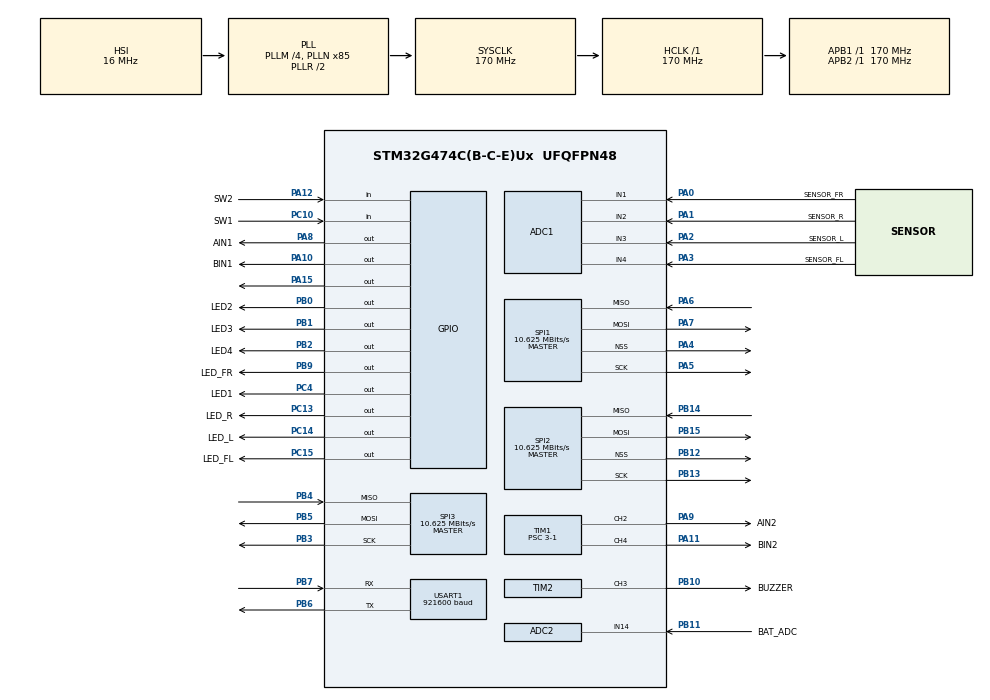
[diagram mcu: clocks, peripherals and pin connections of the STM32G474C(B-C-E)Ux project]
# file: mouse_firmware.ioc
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ADC1.Channel-8\#ChannelRegularConversion=ADC_CHANNEL_1
ADC1.ClockPrescaler=ADC_CLOCK_ASYNC_DIV4
ADC1.ContinuousConvMode=DISABLE
ADC1.DMAContinuousRequests=DISABLE
ADC1.DiscontinuousConvMode=DISABLE
ADC1.EnableRegularConversion=ENABLE
ADC1.NbrOfConversion=1
ADC1.NbrOfConversionFlag=1
ADC1.OffsetNumber-8\#ChannelRegularConversion=ADC_OFFSET_NONE
ADC1.Overrun=ADC_OVR_DATA_PRESERVED
ADC1.Rank-8\#ChannelRegularConversion=1
ADC1.SamplingTime-8\#ChannelRegularConversion=ADC_SAMPLETIME_2CYCLES_5
ADC1.master=1
ADC2.Channel-0\#ChannelRegularConversion=ADC_CHANNEL_14
ADC2.ClockPrescaler=ADC_CLOCK_ASYNC_DIV4
ADC2.ContinuousConvMode=DISABLE
ADC2.DMAContinuousRequests=ENABLE
ADC2.EOCSelection=ADC_EOC_SINGLE_CONV
ADC2.EnableInjectedConversion=DISABLE
ADC2.LowPowerAutoWait=DISABLE
ADC2.NbrOfConversion=1
ADC2.NbrOfConversionFlag=1
ADC2.OffsetNumber-0\#ChannelRegularConversion=ADC_OFFSET_NONE
ADC2.Rank-0\#ChannelRegularConversion=1
ADC2.Rank1_Channel=ADC_CHANNEL_14
ADC2.SamplingTime-0\#ChannelRegularConversion=ADC_SAMPLETIME_12CYCLES_5
Dma.ADC1.0.Direction=DMA_PERIPH_TO_MEMORY
Dma.ADC1.0.EventEnable=DISABLE
Dma.ADC1.0.Instance=DMA1_Channel1
Dma.ADC1.0.MemDataAlignment=DMA_MDATAALIGN_HALFWORD
Dma.ADC1.0.MemInc=DMA_MINC_ENABLE
Dma.ADC1.0.Mode=DMA_NORMAL
Dma.ADC1.0.PeriphDataAlignment=DMA_PDATAALIGN_HALFWORD
Dma.ADC1.0.PeriphInc=DMA_PINC_DISABLE
Dma.ADC1.0.Polarity=HAL_DMAMUX_REQ_GEN_RISING
Dma.ADC1.0.Priority=DMA_PRIORITY_LOW
Dma.ADC1.0.RequestNumber=1
Dma.ADC1.0.SignalID=NONE
Dma.ADC1.0.SyncEnable=DISABLE
Dma.ADC1.0.SyncPolarity=HAL_DMAMUX_SYNC_NO_EVENT
Dma.ADC1.0.SyncRequestNumber=1
Dma.ADC1.0.SyncSignalID=NONE
Dma.ADC2.5.Direction=DMA_PERIPH_TO_MEMORY
Dma.ADC2.5.EventEnable=DISABLE
Dma.ADC2.5.Instance=DMA1_Channel6
Dma.ADC2.5.MemDataAlignment=DMA_MDATAALIGN_HALFWORD
Dma.ADC2.5.MemInc=DMA_MINC_ENABLE
Dma.ADC2.5.Mode=DMA_CIRCULAR
Dma.ADC2.5.PeriphDataAlignment=DMA_PDATAALIGN_HALFWORD
Dma.ADC2.5.PeriphInc=DMA_PINC_DISABLE
Dma.ADC2.5.Polarity=HAL_DMAMUX_REQ_GEN_RISING
Dma.ADC2.5.Priority=DMA_PRIORITY_LOW
Dma.ADC2.5.RequestNumber=1
Dma.ADC2.5.SignalID=NONE
Dma.ADC2.5.SyncEnable=DISABLE
Dma.ADC2.5.SyncPolarity=HAL_DMAMUX_SYNC_NO_EVENT
Dma.ADC2.5.SyncRequestNumber=1
Dma.ADC2.5.SyncSignalID=NONE
Dma.Request0=ADC1
Dma.Request1=SPI2_RX
Dma.Request2=SPI2_TX
Dma.Request3=SPI3_RX
Dma.Request4=SPI3_TX
Dma.Request5=ADC2
Dma.Request6=USART1_TX
Dma.Request7=USART1_RX
Dma.Request8=SPI1_RX
Dma.Request9=SPI1_TX
Dma.SPI1_RX.8.Direction=DMA_PERIPH_TO_MEMORY
Dma.SPI1_RX.8.EventEnable=DISABLE
Dma.SPI1_RX.8.Instance=DMA2_Channel1
Dma.SPI1_RX.8.MemDataAlignment=DMA_MDATAALIGN_HALFWORD
Dma.SPI1_RX.8.MemInc=DMA_MINC_ENABLE
Dma.SPI1_RX.8.Mode=DMA_NORMAL
Dma.SPI1_RX.8.PeriphDataAlignment=DMA_PDATAALIGN_HALFWORD
Dma.SPI1_RX.8.PeriphInc=DMA_PINC_DISABLE
Dma.SPI1_RX.8.Polarity=HAL_DMAMUX_REQ_GEN_RISING
Dma.SPI1_RX.8.Priority=DMA_PRIORITY_LOW
Dma.SPI1_RX.8.RequestNumber=1
Dma.SPI1_RX.8.SignalID=NONE
Dma.SPI1_RX.8.SyncEnable=DISABLE
Dma.SPI1_RX.8.SyncPolarity=HAL_DMAMUX_SYNC_NO_EVENT
Dma.SPI1_RX.8.SyncRequestNumber=1
Dma.SPI1_RX.8.SyncSignalID=NONE
Dma.SPI1_TX.9.Direction=DMA_MEMORY_TO_PERIPH
Dma.SPI1_TX.9.EventEnable=DISABLE
Dma.SPI1_TX.9.Instance=DMA2_Channel2
Dma.SPI1_TX.9.MemDataAlignment=DMA_MDATAALIGN_HALFWORD
Dma.SPI1_TX.9.MemInc=DMA_MINC_ENABLE
Dma.SPI1_TX.9.Mode=DMA_NORMAL
Dma.SPI1_TX.9.PeriphDataAlignment=DMA_PDATAALIGN_HALFWORD
Dma.SPI1_TX.9.PeriphInc=DMA_PINC_DISABLE
Dma.SPI1_TX.9.Polarity=HAL_DMAMUX_REQ_GEN_RISING
Dma.SPI1_TX.9.Priority=DMA_PRIORITY_LOW
Dma.SPI1_TX.9.RequestNumber=1
Dma.SPI1_TX.9.SignalID=NONE
Dma.SPI1_TX.9.SyncEnable=DISABLE
Dma.SPI1_TX.9.SyncPolarity=HAL_DMAMUX_SYNC_NO_EVENT
Dma.SPI1_TX.9.SyncRequestNumber=1
Dma.SPI1_TX.9.SyncSignalID=NONE
Dma.SPI2_RX.1.Direction=DMA_PERIPH_TO_MEMORY
Dma.SPI2_RX.1.EventEnable=DISABLE
Dma.SPI2_RX.1.Instance=DMA1_Channel2
Dma.SPI2_RX.1.MemDataAlignment=DMA_MDATAALIGN_HALFWORD
Dma.SPI2_RX.1.MemInc=DMA_MINC_ENABLE
Dma.SPI2_RX.1.Mode=DMA_NORMAL
Dma.SPI2_RX.1.PeriphDataAlignment=DMA_PDATAALIGN_HALFWORD
Dma.SPI2_RX.1.PeriphInc=DMA_PINC_DISABLE
Dma.SPI2_RX.1.Polarity=HAL_DMAMUX_REQ_GEN_RISING
Dma.SPI2_RX.1.Priority=DMA_PRIORITY_LOW
Dma.SPI2_RX.1.RequestNumber=1
Dma.SPI2_RX.1.SignalID=NONE
Dma.SPI2_RX.1.SyncEnable=DISABLE
Dma.SPI2_RX.1.SyncPolarity=HAL_DMAMUX_SYNC_NO_EVENT
Dma.SPI2_RX.1.SyncRequestNumber=1
Dma.SPI2_RX.1.SyncSignalID=NONE
Dma.SPI2_TX.2.Direction=DMA_MEMORY_TO_PERIPH
Dma.SPI2_TX.2.EventEnable=DISABLE
Dma.SPI2_TX.2.Instance=DMA1_Channel3
Dma.SPI2_TX.2.MemDataAlignment=DMA_MDATAALIGN_HALFWORD
Dma.SPI2_TX.2.MemInc=DMA_MINC_ENABLE
Dma.SPI2_TX.2.Mode=DMA_NORMAL
Dma.SPI2_TX.2.PeriphDataAlignment=DMA_PDATAALIGN_HALFWORD
Dma.SPI2_TX.2.PeriphInc=DMA_PINC_DISABLE
Dma.SPI2_TX.2.Polarity=HAL_DMAMUX_REQ_GEN_RISING
Dma.SPI2_TX.2.Priority=DMA_PRIORITY_LOW
Dma.SPI2_TX.2.RequestNumber=1
Dma.SPI2_TX.2.SignalID=NONE
Dma.SPI2_TX.2.SyncEnable=DISABLE
Dma.SPI2_TX.2.SyncPolarity=HAL_DMAMUX_SYNC_NO_EVENT
Dma.SPI2_TX.2.SyncRequestNumber=1
Dma.SPI2_TX.2.SyncSignalID=NONE
Dma.SPI3_RX.3.Direction=DMA_PERIPH_TO_MEMORY
Dma.SPI3_RX.3.EventEnable=DISABLE
Dma.SPI3_RX.3.Instance=DMA1_Channel4
Dma.SPI3_RX.3.MemDataAlignment=DMA_MDATAALIGN_HALFWORD
Dma.SPI3_RX.3.MemInc=DMA_MINC_ENABLE
Dma.SPI3_RX.3.Mode=DMA_NORMAL
Dma.SPI3_RX.3.PeriphDataAlignment=DMA_PDATAALIGN_HALFWORD
Dma.SPI3_RX.3.PeriphInc=DMA_PINC_DISABLE
Dma.SPI3_RX.3.Polarity=HAL_DMAMUX_REQ_GEN_RISING
Dma.SPI3_RX.3.Priority=DMA_PRIORITY_LOW
Dma.SPI3_RX.3.RequestNumber=1
Dma.SPI3_RX.3.SignalID=NONE
Dma.SPI3_RX.3.SyncEnable=DISABLE
Dma.SPI3_RX.3.SyncPolarity=HAL_DMAMUX_SYNC_NO_EVENT
Dma.SPI3_RX.3.SyncRequestNumber=1
Dma.SPI3_RX.3.SyncSignalID=NONE
Dma.SPI3_TX.4.Direction=DMA_MEMORY_TO_PERIPH
Dma.SPI3_TX.4.EventEnable=DISABLE
Dma.SPI3_TX.4.Instance=DMA1_Channel5
Dma.SPI3_TX.4.MemDataAlignment=DMA_MDATAALIGN_HALFWORD
Dma.SPI3_TX.4.MemInc=DMA_MINC_ENABLE
Dma.SPI3_TX.4.Mode=DMA_NORMAL
Dma.SPI3_TX.4.PeriphDataAlignment=DMA_PDATAALIGN_HALFWORD
Dma.SPI3_TX.4.PeriphInc=DMA_PINC_DISABLE
Dma.SPI3_TX.4.Polarity=HAL_DMAMUX_REQ_GEN_RISING
Dma.SPI3_TX.4.Priority=DMA_PRIORITY_LOW
Dma.SPI3_TX.4.RequestNumber=1
Dma.SPI3_TX.4.SignalID=NONE
Dma.SPI3_TX.4.SyncEnable=DISABLE
Dma.SPI3_TX.4.SyncPolarity=HAL_DMAMUX_SYNC_NO_EVENT
Dma.SPI3_TX.4.SyncRequestNumber=1
Dma.SPI3_TX.4.SyncSignalID=NONE
Dma.USART1_RX.7.Direction=DMA_PERIPH_TO_MEMORY
Dma.USART1_RX.7.EventEnable=DISABLE
Dma.USART1_RX.7.Instance=DMA1_Channel8
Dma.USART1_RX.7.MemDataAlignment=DMA_MDATAALIGN_BYTE
Dma.USART1_RX.7.MemInc=DMA_MINC_ENABLE
Dma.USART1_RX.7.Mode=DMA_NORMAL
Dma.USART1_RX.7.PeriphDataAlignment=DMA_PDATAALIGN_BYTE
Dma.USART1_RX.7.PeriphInc=DMA_PINC_DISABLE
Dma.USART1_RX.7.Polarity=HAL_DMAMUX_REQ_GEN_RISING
Dma.USART1_RX.7.Priority=DMA_PRIORITY_LOW
Dma.USART1_RX.7.RequestNumber=1
Dma.USART1_RX.7.SignalID=NONE
Dma.USART1_RX.7.SyncEnable=DISABLE
Dma.USART1_RX.7.SyncPolarity=HAL_DMAMUX_SYNC_NO_EVENT
Dma.USART1_RX.7.SyncRequestNumber=1
Dma.USART1_RX.7.SyncSignalID=NONE
Dma.USART1_TX.6.Direction=DMA_MEMORY_TO_PERIPH
Dma.USART1_TX.6.EventEnable=DISABLE
Dma.USART1_TX.6.Instance=DMA1_Channel7
Dma.USART1_TX.6.MemDataAlignment=DMA_MDATAALIGN_BYTE
Dma.USART1_TX.6.MemInc=DMA_MINC_ENABLE
Dma.USART1_TX.6.Mode=DMA_NORMAL
Dma.USART1_TX.6.PeriphDataAlignment=DMA_PDATAALIGN_BYTE
Dma.USART1_TX.6.PeriphInc=DMA_PINC_DISABLE
Dma.USART1_TX.6.Polarity=HAL_DMAMUX_REQ_GEN_RISING
Dma.USART1_TX.6.Priority=DMA_PRIORITY_LOW
Dma.USART1_TX.6.RequestNumber=1
Dma.USART1_TX.6.SignalID=NONE
Dma.USART1_TX.6.SyncEnable=DISABLE
Dma.USART1_TX.6.SyncPolarity=HAL_DMAMUX_SYNC_NO_EVENT
Dma.USART1_TX.6.SyncRequestNumber=1
Dma.USART1_TX.6.SyncSignalID=NONE
Mcu.Family=STM32G4
Mcu.Name=STM32G474C(B-C-E)Ux
Mcu.Package=UFQFPN48
NVIC.ADC1_2_IRQn=true\:0\:0\:false\:false\:true\:true\:true\:true
NVIC.DMA1_Channel1_IRQn=true\:0\:0\:false\:false\:true\:false\:true\:true
NVIC.DMA1_Channel2_IRQn=true\:0\:0\:false\:false\:true\:false\:true\:true
NVIC.DMA1_Channel3_IRQn=true\:0\:0\:false\:false\:true\:false\:true\:true
NVIC.DMA1_Channel4_IRQn=true\:0\:0\:false\:false\:true\:false\:true\:true
NVIC.DMA1_Channel5_IRQn=true\:0\:0\:false\:false\:true\:false\:true\:true
NVIC.DMA1_Channel6_IRQn=true\:0\:0\:false\:false\:true\:false\:true\:true
NVIC.DMA1_Channel7_IRQn=true\:0\:0\:false\:false\:true\:false\:true\:true
NVIC.DMA1_Channel8_IRQn=true\:0\:0\:false\:false\:true\:false\:true\:true
NVIC.DMA2_Channel1_IRQn=true\:0\:0\:false\:false\:true\:false\:true\:true
NVIC.DMA2_Channel2_IRQn=true\:0\:0\:false\:false\:true\:false\:true\:true
NVIC.PriorityGroup=NVIC_PRIORITYGROUP_4
NVIC.SPI1_IRQn=true\:0\:0\:false\:false\:true\:true\:true\:true
NVIC.SPI2_IRQn=true\:0\:0\:false\:false\:true\:true\:true\:true
NVIC.SPI3_IRQn=true\:0\:0\:false\:false\:true\:true\:true\:true
NVIC.TIM1_TRG_COM_TIM17_IRQn=true\:0\:0\:false\:false\:true\:true\:true\:true
NVIC.TIM1_UP_TIM16_IRQn=true\:0\:0\:false\:false\:true\:true\:true\:true
NVIC.TIM7_DAC_IRQn=true\:0\:0\:false\:false\:true\:true\:true\:true
NVIC.USART1_IRQn=true\:0\:0\:false\:false\:true\:true\:true\:true
PA0.GPIO_Label=SENSOR_FR
PA0.Mode=IN1-Single-Ended
PA0.Signal=ADC1_IN1
PA1.GPIO_Label=SENSOR_R
PA1.Mode=IN2-Single-Ended
PA1.Signal=ADC1_IN2
PA10.GPIO_Label=BIN1
PA10.Signal=GPIO_Output
PA11.GPIO_Label=BIN2
PA11.Signal=S_TIM1_CH4
PA12.GPIO_Label=SW2
PA12.GPIO_PuPd=GPIO_PULLUP
PA12.Signal=GPIO_Input
PA13.Mode=Serial_Wire
PA13.Signal=SYS_JTMS-SWDIO
PA14.Mode=Serial_Wire
PA14.Signal=SYS_JTCK-SWCLK
PA15.Signal=GPIO_Output
PA2.GPIO_Label=SENSOR_L
PA2.Mode=IN3-Single-Ended
PA2.Signal=ADC1_IN3
PA3.GPIO_Label=SENSOR_FL
PA3.Mode=IN4-Single-Ended
PA3.Signal=ADC1_IN4
PA4.GPIO_Speed=GPIO_SPEED_FREQ_HIGH
PA4.Mode=NSS_Signal_Hard_Output
PA4.Signal=SPI1_NSS
PA5.Mode=Full_Duplex_Master
PA5.Signal=SPI1_SCK
PA6.Mode=Full_Duplex_Master
PA6.Signal=SPI1_MISO
PA7.Mode=Full_Duplex_Master
PA7.Signal=SPI1_MOSI
PA8.GPIO_Label=AIN1
PA8.Signal=GPIO_Output
PA9.GPIO_Label=AIN2
PA9.Signal=S_TIM1_CH2
PB0.GPIO_Label=LED2
PB0.Signal=GPIO_Output
PB1.GPIO_Label=LED3
PB1.Signal=GPIO_Output
PB10.GPIO_Label=BUZZER
PB10.Signal=S_TIM2_CH3
PB11.GPIO_Label=BAT_ADC
PB11.Mode=IN14-Single-Ended
PB11.Signal=ADC2_IN14
PB12.GPIO_Speed=GPIO_SPEED_FREQ_HIGH
PB12.Mode=NSS_Signal_Hard_Output
PB12.Signal=SPI2_NSS
PB13.Mode=Full_Duplex_Master
PB13.Signal=SPI2_SCK
PB14.Mode=Full_Duplex_Master
PB14.Signal=SPI2_MISO
PB15.Mode=Full_Duplex_Master
PB15.Signal=SPI2_MOSI
PB2.GPIO_Label=LED4
PB2.Signal=GPIO_Output
PB3.Mode=Full_Duplex_Master
PB3.Signal=SPI3_SCK
PB4.Mode=Full_Duplex_Master
PB4.Signal=SPI3_MISO
PB5.Mode=Full_Duplex_Master
PB5.Signal=SPI3_MOSI
PB6.Mode=Asynchronous
PB6.Signal=USART1_TX
PB7.Mode=Asynchronous
PB7.Signal=USART1_RX
PB9.GPIO_Label=LED_FR
PB9.Signal=GPIO_Output
PC10.GPIO_Label=SW1
PC10.GPIO_PuPd=GPIO_PULLUP
PC10.Signal=GPIO_Input
PC13.GPIO_Label=LED_R
PC13.Signal=GPIO_Output
PC14-OSC32_IN.GPIO_Label=LED_L
PC14-OSC32_IN.Signal=GPIO_Output
PC15-OSC32_OUT.GPIO_Label=LED_FL
PC15-OSC32_OUT.Signal=GPIO_Output
PC4.GPIO_Label=LED1
PC4.Signal=GPIO_Output
ProjectManager.HeapSize=0x200
ProjectManager.StackSize=0x400
ProjectManager.TargetToolchain=STM32CubeIDE
RCC.ADC12Freq_Value=170000000
RCC.ADC345Freq_Value=170000000
RCC.AHBFreq_Value=170000000
RCC.APB1Freq_Value=170000000
RCC.APB1TimFreq_Value=170000000
RCC.APB2Freq_Value=170000000
RCC.APB2TimFreq_Value=170000000
RCC.CortexFreq_Value=170000000
RCC.EXTERNAL_CLOCK_VALUE=12288000
RCC.HCLKFreq_Value=170000000
RCC.HSE_VALUE=8000000
RCC.HSI48_VALUE=48000000
RCC.HSI_VALUE=16000000
RCC.LSE_VALUE=32768
RCC.PLLM=RCC_PLLM_DIV4
RCC.PLLN=85
RCC.SYSCLKFreq_VALUE=170000000
RCC.SYSCLKSource=RCC_SYSCLKSOURCE_PLLCLK
RCC.USBFreq_Value=170000000
RCC.VCOOutputFreq_Value=340000000
SH.S_TIM1_CH2.0=TIM1_CH2,PWM Generation2 CH2
SH.S_TIM1_CH4.0=TIM1_CH4,PWM Generation4 CH4
SH.S_TIM2_CH3.0=TIM2_CH3,PWM Generation3 CH3
SPI1.BaudRatePrescaler=SPI_BAUDRATEPRESCALER_16
SPI1.CalculateBaudRate=10.625 MBits/s
SPI1.DataSize=SPI_DATASIZE_16BIT
SPI1.Direction=SPI_DIRECTION_2LINES
SPI1.Mode=SPI_MODE_MASTER
SPI1.NSSPMode=SPI_NSS_PULSE_ENABLE
SPI1.VirtualNSS=VM_NSSHARD
SPI1.VirtualType=VM_MASTER
SPI2.BaudRatePrescaler=SPI_BAUDRATEPRESCALER_16
SPI2.CalculateBaudRate=10.625 MBits/s
SPI2.DataSize=SPI_DATASIZE_16BIT
SPI2.Direction=SPI_DIRECTION_2LINES
SPI2.Mode=SPI_MODE_MASTER
SPI2.NSSPMode=SPI_NSS_PULSE_ENABLE
SPI2.VirtualNSS=VM_NSSHARD
SPI2.VirtualType=VM_MASTER
SPI3.BaudRatePrescaler=SPI_BAUDRATEPRESCALER_16
SPI3.CLKPhase=SPI_PHASE_2EDGE
SPI3.CLKPolarity=SPI_POLARITY_HIGH
SPI3.CalculateBaudRate=10.625 MBits/s
SPI3.DataSize=SPI_DATASIZE_8BIT
SPI3.Direction=SPI_DIRECTION_2LINES
SPI3.Mode=SPI_MODE_MASTER
SPI3.VirtualType=VM_MASTER
TIM1.Channel-PWM\ Generation2\ CH2=TIM_CHANNEL_2
TIM1.Channel-PWM\ Generation4\ CH4=TIM_CHANNEL_4
TIM1.PeriodNoDither=1000
TIM1.Prescaler=3-1
TIM16.PeriodNoDither=10000-1
TIM16.Prescaler=170-1
TIM17.PeriodNoDither=1000
TIM17.Prescaler=170-1
TIM2.Channel-PWM\ Generation3\ CH3=TIM_CHANNEL_3
TIM2.PeriodNoDither=2000
TIM2.Prescaler=1700
TIM2.PulseNoDither_3=0
TIM7.PeriodNoDither=125
TIM7.Prescaler=17-1
USART1.BaudRate=921600
USART1.VirtualMode-Asynchronous=VM_ASYNC
VP_TIM16_VS_ClockSourceINT.Mode=Enable_Timer
VP_TIM17_VS_ClockSourceINT.Mode=Enable_Timer
VP_TIM7_VS_ClockSourceINT.Mode=Enable_Timer
board=custom

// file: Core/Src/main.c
/* USER CODE BEGIN Header */
/**
  ******************************************************************************
  * @file           : main.c
  * @brief          : Main program body
  ******************************************************************************
  * @attention
  *
  * Copyright (c) 2023 STMicroelectronics.
  * All rights reserved.
  *
  * This software is licensed under terms that can be found in the LICENSE file
  * in the root directory of this software component.
  * If no LICENSE file comes with this software, it is provided AS-IS.
  *
  ******************************************************************************
  */
/* USER CODE END Header */
#include "main.h"
#include "adc.h"
#include "dma.h"
#include "spi.h"
#include "tim.h"
#include "usart.h"
#include "gpio.h"

/* USER CODE BEGIN Includes */
#include "c_wrapper.h"
/* USER CODE END Includes */

/* USER CODE BEGIN PD */
int _write(int file, char *ptr, int len){
	HAL_UART_Transmit_DMA(&huart1, (uint8_t *)ptr, len);
	return len;
}

/* USER CODE END PD */

void SystemClock_Config(void);

int main(void)
{

  /* MCU Configuration--------------------------------------------------------*/

  /* Reset of all peripherals, Initializes the Flash interface and the Systick. */
  HAL_Init();

  /* Configure the system clock */
  SystemClock_Config();

  /* Initialize all configured peripherals */
  MX_GPIO_Init();
  MX_DMA_Init();
  MX_ADC1_Init();
  MX_SPI1_Init();
  MX_SPI2_Init();
  MX_SPI3_Init();
  MX_TIM1_Init();
  MX_TIM2_Init();
  MX_USART1_UART_Init();
  MX_TIM16_Init();
  MX_TIM17_Init();
  MX_ADC2_Init();
  MX_TIM7_Init();
  /* USER CODE BEGIN 2 */
  Init();
  /* USER CODE END 2 */

  /* Infinite loop */
  while (1)
  {

    /* USER CODE BEGIN 3 */
	  Loop();
	  //HAL_Delay(50);
  }
  /* USER CODE END 3 */
}

void SystemClock_Config(void)
{
  RCC_OscInitTypeDef RCC_OscInitStruct = {0};
  RCC_ClkInitTypeDef RCC_ClkInitStruct = {0};

  /** Configure the main internal regulator output voltage
  */
  HAL_PWREx_ControlVoltageScaling(PWR_REGULATOR_VOLTAGE_SCALE1_BOOST);

  /** Initializes the RCC Oscillators according to the specified parameters
  * in the RCC_OscInitTypeDef structure.
  */
  RCC_OscInitStruct.OscillatorType = RCC_OSCILLATORTYPE_HSI;
  RCC_OscInitStruct.HSIState = RCC_HSI_ON;
  RCC_OscInitStruct.HSICalibrationValue = RCC_HSICALIBRATION_DEFAULT;
  RCC_OscInitStruct.PLL.PLLState = RCC_PLL_ON;
  RCC_OscInitStruct.PLL.PLLSource = RCC_PLLSOURCE_HSI;
  RCC_OscInitStruct.PLL.PLLM = RCC_PLLM_DIV4;
  RCC_OscInitStruct.PLL.PLLN = 85;
  RCC_OscInitStruct.PLL.PLLP = RCC_PLLP_DIV2;
  RCC_OscInitStruct.PLL.PLLQ = RCC_PLLQ_DIV2;
  RCC_OscInitStruct.PLL.PLLR = RCC_PLLR_DIV2;
  if (HAL_RCC_OscConfig(&RCC_OscInitStruct) != HAL_OK)
  {
    Error_Handler();
  }

  /** Initializes the CPU, AHB and APB buses clocks
  */
  RCC_ClkInitStruct.ClockType = RCC_CLOCKTYPE_HCLK|RCC_CLOCKTYPE_SYSCLK
                              |RCC_CLOCKTYPE_PCLK1|RCC_CLOCKTYPE_PCLK2;
  RCC_ClkInitStruct.SYSCLKSource = RCC_SYSCLKSOURCE_PLLCLK;
  RCC_ClkInitStruct.AHBCLKDivider = RCC_SYSCLK_DIV1;
  RCC_ClkInitStruct.APB1CLKDivider = RCC_HCLK_DIV1;
  RCC_ClkInitStruct.APB2CLKDivider = RCC_HCLK_DIV1;

  if (HAL_RCC_ClockConfig(&RCC_ClkInitStruct, FLASH_LATENCY_4) != HAL_OK)
  {
    Error_Handler();
  }
}

void Error_Handler(void)
{
  __disable_irq();
  while (1)
  {
  }
}
